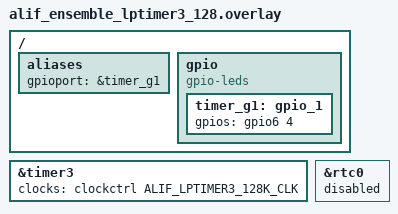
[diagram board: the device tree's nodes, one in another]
/* Copyright (c) 2024 Alif Semiconductor
 *
 * SPDX-License-Identifier: Apache-2.0
 */

#include <zephyr/dt-bindings/clock/alif_ensemble_clocks.h>


/ {
	aliases {
		gpioport = &timer_g1;
	};

	gpio {
		compatible = "gpio-leds";
		timer_g1: gpio_1 {
			gpios = <&gpio6 4 0>;
		};
	};
};
/*
 * Enabling lptimer & disabling rtc for this sample application
 */

&timer3 {
	clocks = <&clockctrl ALIF_LPTIMER3_128K_CLK>;
	status = "okay";
};

&rtc0 {
	status = "disabled";
};
